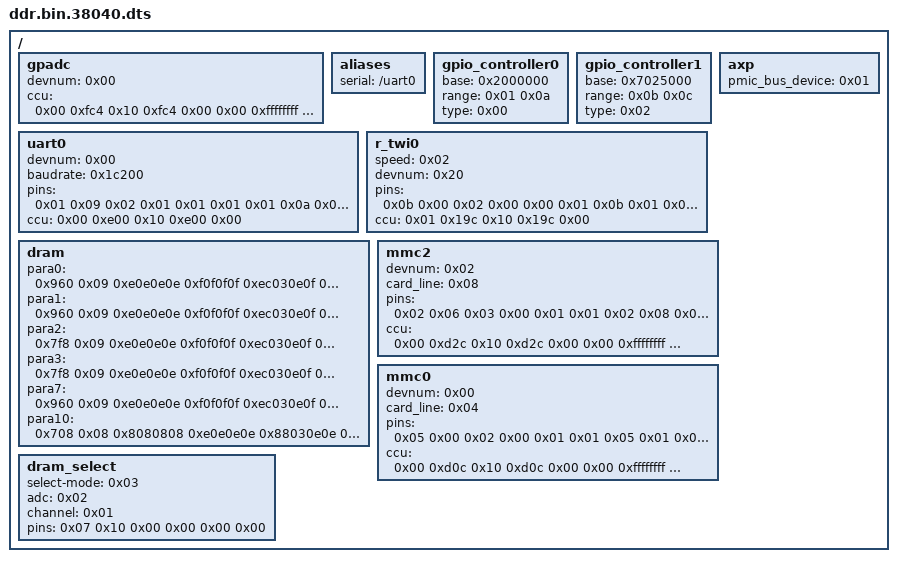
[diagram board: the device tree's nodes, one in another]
/dts-v1/;

/ {

	gpadc: gpadc {
		devnum = <0x00>;
		ccu = <0x00 0xfc4 0x10 0xfc4 0x00 0x00 0xffffffff 0x00 0xfc0 0x1f>;
		phandle = <0x02>;
	};

	aliases: aliases {
		serial = "/uart0";
		phandle = <0x03>;
	};

	gpio_controller0: gpio_controller0 {
		base = <0x2000000>;
		range = <0x01 0x0a>;
		type = <0x00>;
		phandle = <0x04>;
	};

	gpio_controller1: gpio_controller1 {
		base = <0x7025000>;
		range = <0x0b 0x0c>;
		type = <0x02>;
		phandle = <0x05>;
	};

	uart0: uart0 {
		devnum = <0x00>;
		baudrate = <0x1c200>;
		pins = <0x01 0x09 0x02 0x01 0x01 0x01 0x01 0x0a 0x02 0x01 0x01 0x01>;
		ccu = <0x00 0xe00 0x10 0xe00 0x00>;
		phandle = <0x06>;
	};

	r_twi0: r_twi0 {
		speed = <0x02>;
		devnum = <0x20>;
		pins = <0x0b 0x00 0x02 0x00 0x00 0x01 0x0b 0x01 0x02 0x00 0x00 0x01>;
		ccu = <0x01 0x19c 0x10 0x19c 0x00>;
		phandle = <0x01>;
	};

	axp: axp {
		pmic_bus_device = <0x01>;
		phandle = <0x07>;
	};

	dram: dram {
		para0 = <0x960 0x09 0xe0e0e0e 0xf0f0f0f 0xec030e0f 0x00 0xa0fa 0x1001 0x00 0x00 0x00 0x06 0x00 0x00 0x00 0x13 0x44 0x00 0x2e 0x00 0x06 0x00 0x4040 0x00 0x170b0703 0x3800 0x3514 0x325f0000 0x00 0x00 0x65 0x00>;
		para1 = <0x960 0x09 0xe0e0e0e 0xf0f0f0f 0xec030e0f 0x00 0xa10a 0x1001 0x00 0x00 0x00 0x06 0x00 0x00 0x00 0x13 0x44 0x00 0x2e 0x00 0x06 0x00 0x4040 0x00 0x170b0703 0x3800 0x3514 0x325f0000 0x00 0x00 0x10065 0x00>;
		para2 = <0x7f8 0x09 0xe0e0e0e 0xf0f0f0f 0xec030e0f 0x00 0xa10a 0x1001 0x00 0x00 0x00 0x06 0x00 0x00 0x00 0x13 0x44 0x00 0x2e 0x00 0x86 0x00 0x7004040 0x00 0x13090603 0x3800 0x3514 0xb25f0000 0x00 0x00 0x65 0x00>;
		para3 = <0x7f8 0x09 0xe0e0e0e 0xf0f0f0f 0xec030e0f 0x00 0xa11a 0x1001 0x00 0x00 0x00 0x06 0x00 0x00 0x00 0x13 0x44 0x00 0x2e 0x00 0x86 0x00 0x7004040 0x00 0x13090603 0x3800 0x3514 0xb25f0000 0x00 0x00 0x10065 0x00>;
		para7 = <0x960 0x09 0xe0e0e0e 0xf0f0f0f 0xec030e0f 0x00 0xa10a 0x01 0x00 0x00 0x00 0x06 0x00 0x00 0x00 0x12 0x44 0x00 0x34 0x00 0x06 0x00 0x4040 0x00 0x170b0703 0x3800 0x3514 0x325f0000 0x00 0x00 0x65 0x00>;
		para10 = <0x708 0x08 0x8080808 0xe0e0e0e 0x88030e0e 0x00 0x311a 0x1001 0x00 0x8c 0x00 0x33 0x00 0x00 0x00 0x04 0x72 0x08 0x1d 0x00 0x00 0x24 0x00 0x00 0x11080503 0x200000 0x402a 0x721f0000 0x00 0x00 0x64 0x00>;
		phandle = <0x08>;
	};

	mmc2: mmc2 {
		devnum = <0x02>;
		card_line = <0x08>;
		pins = <0x02 0x06 0x03 0x00 0x01 0x01 0x02 0x08 0x03 0x00 0x01 0x01 0x02 0x09 0x03 0x00 0x01 0x01 0x02 0x0a 0x03 0x00 0x01 0x01 0x02 0x0b 0x03 0x00 0x01 0x01 0x02 0x0d 0x03 0x00 0x01 0x01 0x02 0x0e 0x03 0x00 0x01 0x01 0x02 0x0f 0x03 0x00 0x01 0x01 0x02 0x10 0x03 0x00 0x01 0x01 0x02 0x00 0x03 0x00 0x03 0x02 0x02 0x01 0x03 0x00 0x03 0x01 0x02 0x05 0x03 0x00 0x01 0x01>;
		ccu = <0x00 0xd2c 0x10 0xd2c 0x00 0x00 0xffffffff 0x00 0xd20 0x1f>;
		phandle = <0x09>;
	};

	mmc0: mmc0 {
		devnum = <0x00>;
		card_line = <0x04>;
		pins = <0x05 0x00 0x02 0x00 0x01 0x01 0x05 0x01 0x02 0x00 0x01 0x01 0x05 0x02 0x02 0x00 0x03 0x01 0x05 0x03 0x02 0x00 0x01 0x01 0x05 0x04 0x02 0x00 0x01 0x01 0x05 0x05 0x02 0x00 0x01 0x01>;
		ccu = <0x00 0xd0c 0x10 0xd0c 0x00 0x00 0xffffffff 0x00 0xd00 0x1f>;
		phandle = <0x0a>;
	};

	dram_select: dram_select {
		select-mode = <0x03>;
		adc = <0x02>;
		channel = <0x01>;
		pins = <0x07 0x10 0x00 0x00 0x00 0x00>;
		phandle = <0x0b>;
	};

	__symbols__ {
		gpadc = "/gpadc";
		aliases = "/aliases";
		gpio_controller0 = "/gpio_controller0";
		gpio_controller1 = "/gpio_controller1";
		uart0 = "/uart0";
		r_twi0 = "/r_twi0";
		axp = "/axp";
		dram = "/dram";
		mmc2 = "/mmc2";
		mmc0 = "/mmc0";
		dram_select = "/dram_select";
	};
};
